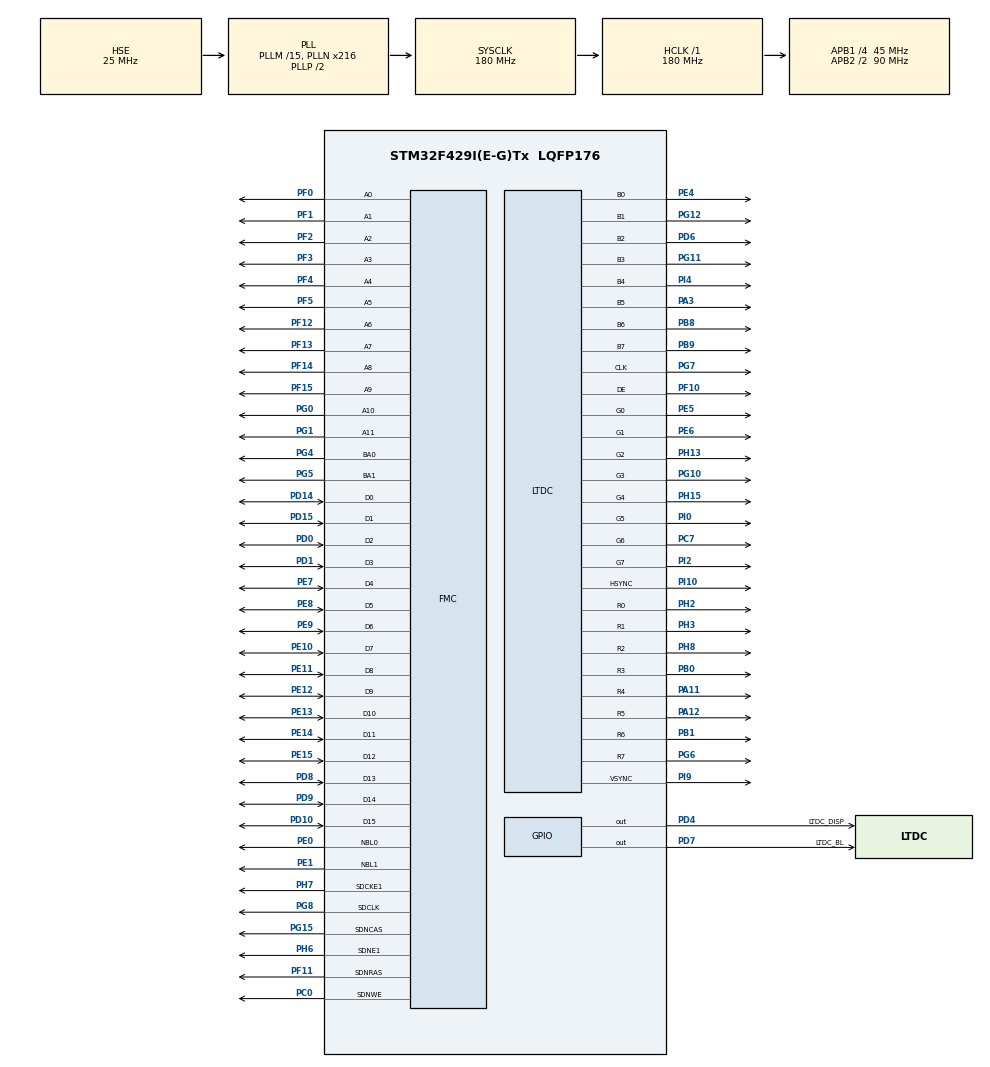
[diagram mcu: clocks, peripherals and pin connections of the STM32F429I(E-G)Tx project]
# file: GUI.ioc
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DMA2D.ColorMode=DMA2D_OUTPUT_RGB565
DMA2D.Mode=DMA2D_R2M
FMC.CASLatency2=FMC_SDRAM_CAS_LATENCY_2
FMC.ExitSelfRefreshDelay2=7
FMC.LoadToActiveDelay2=2
FMC.RCDDelay2=2
FMC.RPDelay2=2
FMC.ReadBurst2=FMC_SDRAM_RBURST_ENABLE
FMC.RowCycleDelay2=7
FMC.SDClockPeriod2=FMC_SDRAM_CLOCK_PERIOD_2
FMC.SelfRefreshTime2=4
FMC.WriteRecoveryTime2=3
LTDC.ActiveH=HEIGHT
LTDC.ActiveW=WIDTH
LTDC.Alpha_L0=255
LTDC.Alpha_L1=255
LTDC.BlendingFactor1_L0=LTDC_BLENDING_FACTOR1_PAxCA
LTDC.BlendingFactor1_L1=LTDC_BLENDING_FACTOR1_PAxCA
LTDC.BlendingFactor2_L0=LTDC_BLENDING_FACTOR2_PAxCA
LTDC.BlendingFactor2_L1=LTDC_BLENDING_FACTOR2_PAxCA
LTDC.FBStartAdress_L0=0xD0000000
LTDC.FBStartAdress_L1=(0xD0000000+800*480*3)
LTDC.HBP=HBP
LTDC.HFP=HFP
LTDC.HSync=HSW
LTDC.ImageHeight_L0=HEIGHT
LTDC.ImageHeight_L1=HEIGHT
LTDC.ImageWidth_L0=WIDTH
LTDC.ImageWidth_L1=WIDTH
LTDC.Layers=1
LTDC.PixelFormat_L0=LTDC_PIXEL_FORMAT_RGB565
LTDC.Red=0
LTDC.VBP=VBP
LTDC.VFP=VFP
LTDC.VSync=VSW
LTDC.WindowX0_L0=0
LTDC.WindowX0_L1=0
LTDC.WindowX1_L0=799
LTDC.WindowX1_L1=799
LTDC.WindowY0_L0=0
LTDC.WindowY0_L1=0
LTDC.WindowY1_L0=479
LTDC.WindowY1_L1=479
Mcu.Family=STM32F4
Mcu.Name=STM32F429I(E-G)Tx
Mcu.Package=LQFP176
Mcu.UserConstants=HBP,46;VBP,23;HSW,1;VSW,1;HFP,20;VFP,22;WIDTH,800;HEIGHT,480
NVIC.DMA2D_IRQn=true\:0\:0\:false\:false\:true\:true\:true\:true
NVIC.LTDC_IRQn=true\:0\:0\:false\:false\:true\:true\:true\:true
NVIC.PriorityGroup=NVIC_PRIORITYGROUP_4
NVIC.RCC_IRQn=true\:0\:0\:false\:false\:true\:true\:false\:true
PA0/WKUP.Mode=SYS_WakeUp0
PA0/WKUP.Signal=SYS_WKUP
PA11.GPIO_Speed=GPIO_SPEED_FREQ_VERY_HIGH
PA11.Mode=RGB888
PA11.Signal=LTDC_R4
PA12.GPIO_Speed=GPIO_SPEED_FREQ_VERY_HIGH
PA12.Mode=RGB888
PA12.Signal=LTDC_R5
PA13.Mode=JTAG_5_pins
PA13.Signal=SYS_JTMS-SWDIO
PA14.Mode=JTAG_5_pins
PA14.Signal=SYS_JTCK-SWCLK
PA15.Mode=JTAG_5_pins
PA15.Signal=SYS_JTDI
PA3.GPIO_Speed=GPIO_SPEED_FREQ_VERY_HIGH
PA3.Mode=RGB888
PA3.Signal=LTDC_B5
PB0.GPIO_Speed=GPIO_SPEED_FREQ_VERY_HIGH
PB0.Mode=RGB888
PB0.Signal=LTDC_R3
PB1.GPIO_Speed=GPIO_SPEED_FREQ_VERY_HIGH
PB1.Mode=RGB888
PB1.Signal=LTDC_R6
PB3.Mode=JTAG_5_pins
PB3.Signal=SYS_JTDO-SWO
PB4.Mode=JTAG_5_pins
PB4.Signal=SYS_JTRST
PB8.GPIO_Speed=GPIO_SPEED_FREQ_VERY_HIGH
PB8.Mode=RGB888
PB8.Signal=LTDC_B6
PB9.GPIO_Speed=GPIO_SPEED_FREQ_VERY_HIGH
PB9.Mode=RGB888
PB9.Signal=LTDC_B7
PC0.Signal=FMC_SDNWE
PC7.GPIO_Speed=GPIO_SPEED_FREQ_VERY_HIGH
PC7.Mode=RGB888
PC7.Signal=LTDC_G6
PD0.Signal=FMC_D2_DA2
PD1.Signal=FMC_D3_DA3
PD10.Signal=FMC_D15_DA15
PD14.Signal=FMC_D0_DA0
PD15.Signal=FMC_D1_DA1
PD4.GPIO_Label=LTDC_DISP
PD4.GPIO_Speed=GPIO_SPEED_FREQ_VERY_HIGH
PD4.Signal=GPIO_Output
PD6.GPIO_Speed=GPIO_SPEED_FREQ_VERY_HIGH
PD6.Mode=RGB888
PD6.Signal=LTDC_B2
PD7.GPIO_Label=LTDC_BL
PD7.GPIO_Speed=GPIO_SPEED_FREQ_VERY_HIGH
PD7.Signal=GPIO_Output
PD8.Signal=FMC_D13_DA13
PD9.Signal=FMC_D14_DA14
PE0.Signal=FMC_NBL0
PE1.Signal=FMC_NBL1
PE10.Signal=FMC_D7_DA7
PE11.Signal=FMC_D8_DA8
PE12.Signal=FMC_D9_DA9
PE13.Signal=FMC_D10_DA10
PE14.Signal=FMC_D11_DA11
PE15.Signal=FMC_D12_DA12
PE4.GPIO_Speed=GPIO_SPEED_FREQ_VERY_HIGH
PE4.Mode=RGB888
PE4.Signal=LTDC_B0
PE5.GPIO_Speed=GPIO_SPEED_FREQ_VERY_HIGH
PE5.Mode=RGB888
PE5.Signal=LTDC_G0
PE6.GPIO_Speed=GPIO_SPEED_FREQ_VERY_HIGH
PE6.Mode=RGB888
PE6.Signal=LTDC_G1
PE7.Signal=FMC_D4_DA4
PE8.Signal=FMC_D5_DA5
PE9.Signal=FMC_D6_DA6
PF0.Signal=FMC_A0
PF1.Signal=FMC_A1
PF10.GPIO_Speed=GPIO_SPEED_FREQ_VERY_HIGH
PF10.Mode=RGB888
PF10.Signal=LTDC_DE
PF11.Signal=FMC_SDNRAS
PF12.Signal=FMC_A6
PF13.Signal=FMC_A7
PF14.Signal=FMC_A8
PF15.Signal=FMC_A9
PF2.Signal=FMC_A2
PF3.Signal=FMC_A3
PF4.Signal=FMC_A4
PF5.Signal=FMC_A5
PG0.Signal=FMC_A10
PG1.Signal=FMC_A11
PG10.GPIO_Speed=GPIO_SPEED_FREQ_VERY_HIGH
PG10.Mode=RGB888
PG10.Signal=LTDC_G3
PG11.GPIO_Speed=GPIO_SPEED_FREQ_VERY_HIGH
PG11.Mode=RGB888
PG11.Signal=LTDC_B3
PG12.GPIO_Speed=GPIO_SPEED_FREQ_VERY_HIGH
PG12.Mode=RGB888
PG12.Signal=LTDC_B1
PG15.Signal=FMC_SDNCAS
PG4.Signal=FMC_A14_BA0
PG5.Signal=FMC_A15_BA1
PG6.GPIO_Speed=GPIO_SPEED_FREQ_VERY_HIGH
PG6.Mode=RGB888
PG6.Signal=LTDC_R7
PG7.GPIO_Speed=GPIO_SPEED_FREQ_VERY_HIGH
PG7.Mode=RGB888
PG7.Signal=LTDC_CLK
PG8.Signal=FMC_SDCLK
PH0/OSC_IN.Mode=HSE-External-Oscillator
PH0/OSC_IN.Signal=RCC_OSC_IN
PH1/OSC_OUT.Mode=HSE-External-Oscillator
PH1/OSC_OUT.Signal=RCC_OSC_OUT
PH13.GPIO_Speed=GPIO_SPEED_FREQ_VERY_HIGH
PH13.Mode=RGB888
PH13.Signal=LTDC_G2
PH15.GPIO_Speed=GPIO_SPEED_FREQ_VERY_HIGH
PH15.Mode=RGB888
PH15.Signal=LTDC_G4
PH2.GPIO_Speed=GPIO_SPEED_FREQ_VERY_HIGH
PH2.Mode=RGB888
PH2.Signal=LTDC_R0
PH3.GPIO_Speed=GPIO_SPEED_FREQ_VERY_HIGH
PH3.Mode=RGB888
PH3.Signal=LTDC_R1
PH6.Mode=SdramChipSelect2_2
PH6.Signal=FMC_SDNE1
PH7.Mode=SdramChipSelect2_2
PH7.Signal=FMC_SDCKE1
PH8.GPIO_Speed=GPIO_SPEED_FREQ_VERY_HIGH
PH8.Mode=RGB888
PH8.Signal=LTDC_R2
PI0.GPIO_Speed=GPIO_SPEED_FREQ_VERY_HIGH
PI0.Mode=RGB888
PI0.Signal=LTDC_G5
PI10.GPIO_Speed=GPIO_SPEED_FREQ_VERY_HIGH
PI10.Mode=RGB888
PI10.Signal=LTDC_HSYNC
PI2.GPIO_Speed=GPIO_SPEED_FREQ_VERY_HIGH
PI2.Mode=RGB888
PI2.Signal=LTDC_G7
PI4.GPIO_Speed=GPIO_SPEED_FREQ_VERY_HIGH
PI4.Mode=RGB888
PI4.Signal=LTDC_B4
PI9.GPIO_Speed=GPIO_SPEED_FREQ_VERY_HIGH
PI9.Mode=RGB888
PI9.Signal=LTDC_VSYNC
ProjectManager.HeapSize=0x200
ProjectManager.StackSize=0x30000
ProjectManager.TargetToolchain=MDK-ARM V5.27
RCC.48MHZClocksFreq_Value=90000000
RCC.AHBFreq_Value=180000000
RCC.APB1CLKDivider=RCC_HCLK_DIV4
RCC.APB1Freq_Value=45000000
RCC.APB1TimFreq_Value=90000000
RCC.APB2CLKDivider=RCC_HCLK_DIV2
RCC.APB2Freq_Value=90000000
RCC.APB2TimFreq_Value=180000000
RCC.CortexFreq_Value=180000000
RCC.HCLKFreq_Value=180000000
RCC.HSE_VALUE=25000000
RCC.HSI_VALUE=16000000
RCC.LSE_VALUE=32768
RCC.PLLM=15
RCC.PLLN=216
RCC.PLLSAIN=60
RCC.PLLSourceVirtual=RCC_PLLSOURCE_HSE
RCC.SYSCLKFreq_VALUE=180000000
RCC.SYSCLKSource=RCC_SYSCLKSOURCE_PLLCLK
RCC.VCOOutputFreq_Value=360000000
SH.FMC_A0.0=FMC_A0,12b-sda2
SH.FMC_A1.0=FMC_A1,12b-sda2
SH.FMC_A10.0=FMC_A10,12b-sda2
SH.FMC_A11.0=FMC_A11,12b-sda2
SH.FMC_A14_BA0.0=FMC_BA0,FourSdramBanks2
SH.FMC_A15_BA1.0=FMC_BA1,FourSdramBanks2
SH.FMC_A2.0=FMC_A2,12b-sda2
SH.FMC_A3.0=FMC_A3,12b-sda2
SH.FMC_A4.0=FMC_A4,12b-sda2
SH.FMC_A5.0=FMC_A5,12b-sda2
SH.FMC_A6.0=FMC_A6,12b-sda2
SH.FMC_A7.0=FMC_A7,12b-sda2
SH.FMC_A8.0=FMC_A8,12b-sda2
SH.FMC_A9.0=FMC_A9,12b-sda2
SH.FMC_D0_DA0.0=FMC_D0,sd-16b-d2
SH.FMC_D10_DA10.0=FMC_D10,sd-16b-d2
SH.FMC_D11_DA11.0=FMC_D11,sd-16b-d2
SH.FMC_D12_DA12.0=FMC_D12,sd-16b-d2
SH.FMC_D13_DA13.0=FMC_D13,sd-16b-d2
SH.FMC_D14_DA14.0=FMC_D14,sd-16b-d2
SH.FMC_D15_DA15.0=FMC_D15,sd-16b-d2
SH.FMC_D1_DA1.0=FMC_D1,sd-16b-d2
SH.FMC_D2_DA2.0=FMC_D2,sd-16b-d2
SH.FMC_D3_DA3.0=FMC_D3,sd-16b-d2
SH.FMC_D4_DA4.0=FMC_D4,sd-16b-d2
SH.FMC_D5_DA5.0=FMC_D5,sd-16b-d2
SH.FMC_D6_DA6.0=FMC_D6,sd-16b-d2
SH.FMC_D7_DA7.0=FMC_D7,sd-16b-d2
SH.FMC_D8_DA8.0=FMC_D8,sd-16b-d2
SH.FMC_D9_DA9.0=FMC_D9,sd-16b-d2
SH.FMC_NBL0.0=FMC_NBL0,Sd2ByteEnable2
SH.FMC_NBL1.0=FMC_NBL1,Sd2ByteEnable2
SH.FMC_SDCLK.0=FMC_SDCLK,12b-sda2
SH.FMC_SDNCAS.0=FMC_SDNCAS,12b-sda2
SH.FMC_SDNRAS.0=FMC_SDNRAS,12b-sda2
SH.FMC_SDNWE.0=FMC_SDNWE,12b-sda2
VP_CRC_VS_CRC.Mode=CRC_Activate
VP_DMA2D_VS_DMA2D.Mode=DMA2D_Activate
board=custom

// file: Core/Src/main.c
/* USER CODE BEGIN Header */
/**
  ******************************************************************************
  * @file           : main.c
  * @brief          : Main program body
  ******************************************************************************
  * @attention
  *
  * <h2><center>&copy; Copyright (c) 2021 STMicroelectronics.
  * All rights reserved.</center></h2>
  *
  * This software component is licensed by ST under BSD 3-Clause license,
  * the "License"; You may not use this file except in compliance with the
  * License. You may obtain a copy of the License at:
  *                        opensource.org/licenses/BSD-3-Clause
  *
  ******************************************************************************
  */
/* USER CODE END Header */
#include "main.h"
#include "crc.h"
#include "dma2d.h"
#include "ltdc.h"
#include "gpio.h"
#include "fmc.h"

/* USER CODE BEGIN Includes */
#include "test.h"
/* USER CODE END Includes */

/* USER CODE BEGIN PD */
#define DEBUG 1
/* USER CODE END PD */

void SystemClock_Config(void);

int main(void)
{
  /* USER CODE BEGIN 1 */
  int k=1;
	static int p;
  /* USER CODE END 1 */

  /* MCU Configuration--------------------------------------------------------*/

  /* Reset of all peripherals, Initializes the Flash interface and the Systick. */
  HAL_Init();

  /* Configure the system clock */
  SystemClock_Config();

  /* Initialize all configured peripherals */
	MX_CRC_Init();
  MX_GPIO_Init();
  MX_FMC_Init();

  MX_DMA2D_Init();
  MX_LTDC_Init();

  /* USER CODE BEGIN 2 */

	#if DEBUG
	//gpio_test();
	 //SDRAM_test();
	#endif

  /* USER CODE END 2 */

  /* Infinite loop */
  while (1)
  {

  }
}

void SystemClock_Config(void)
{
  RCC_OscInitTypeDef RCC_OscInitStruct = {0};
  RCC_ClkInitTypeDef RCC_ClkInitStruct = {0};

  /** Configure the main internal regulator output voltage
  */
  __HAL_RCC_PWR_CLK_ENABLE();
  __HAL_PWR_VOLTAGESCALING_CONFIG(PWR_REGULATOR_VOLTAGE_SCALE1);

  /** Initializes the RCC Oscillators according to the specified parameters
  * in the RCC_OscInitTypeDef structure.
  */
  RCC_OscInitStruct.OscillatorType = RCC_OSCILLATORTYPE_HSE;
  RCC_OscInitStruct.HSEState = RCC_HSE_ON;
  RCC_OscInitStruct.PLL.PLLState = RCC_PLL_ON;
  RCC_OscInitStruct.PLL.PLLSource = RCC_PLLSOURCE_HSE;
  RCC_OscInitStruct.PLL.PLLM = 15;
  RCC_OscInitStruct.PLL.PLLN = 216;
  RCC_OscInitStruct.PLL.PLLP = RCC_PLLP_DIV2;
  RCC_OscInitStruct.PLL.PLLQ = 4;
  if (HAL_RCC_OscConfig(&RCC_OscInitStruct) != HAL_OK)
  {
    Error_Handler();
  }

  /** Activate the Over-Drive mode
  */
  if (HAL_PWREx_EnableOverDrive() != HAL_OK)
  {
    Error_Handler();
  }

  /** Initializes the CPU, AHB and APB buses clocks
  */
  RCC_ClkInitStruct.ClockType = RCC_CLOCKTYPE_HCLK|RCC_CLOCKTYPE_SYSCLK
                              |RCC_CLOCKTYPE_PCLK1|RCC_CLOCKTYPE_PCLK2;
  RCC_ClkInitStruct.SYSCLKSource = RCC_SYSCLKSOURCE_PLLCLK;
  RCC_ClkInitStruct.AHBCLKDivider = RCC_SYSCLK_DIV1;
  RCC_ClkInitStruct.APB1CLKDivider = RCC_HCLK_DIV4;
  RCC_ClkInitStruct.APB2CLKDivider = RCC_HCLK_DIV2;

  if (HAL_RCC_ClockConfig(&RCC_ClkInitStruct, FLASH_LATENCY_5) != HAL_OK)
  {
    Error_Handler();
  }
}

void Error_Handler(void)
{
  __disable_irq();
  while (1)
  {
  }
}
